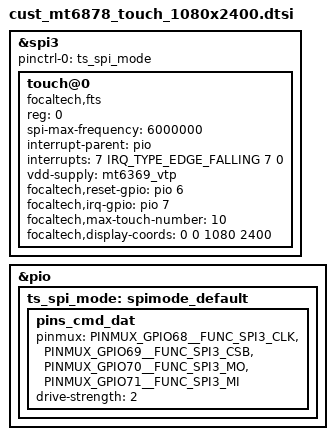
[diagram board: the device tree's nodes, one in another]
// SPDX-License-Identifier: (GPL-2.0 OR MIT)
/*
 * Copyright (C) 2020 MediaTek Inc.
 */

/* TOUCH start */

&spi3 {
	status = "okay";
	#address-cells = <1>;
	#size-cells = <0>;
	pinctrl-names = "default";
	pinctrl-0 = <&ts_spi_mode>;

	touch@0 {
		status = "okay";
		compatible = "focaltech,fts";
		reg = <0>;
		spi-max-frequency = <6000000>;
		interrupt-parent = <&pio>;
		interrupts = <7 IRQ_TYPE_EDGE_FALLING 7 0>;
		vdd-supply = <&mt6369_vtp>;
		//vcc_i2c-supply = <&mt6377_vio18>;
		focaltech,reset-gpio = <&pio 6 0x0>;
		focaltech,irq-gpio = <&pio 7 0x0>;
		focaltech,max-touch-number = <10>;
		focaltech,display-coords = <0 0 1080 2400>;
	};
};
&pio {

	ts_spi_mode: spimode_default {
		pins_cmd_dat {
			pinmux = <PINMUX_GPIO68__FUNC_SPI3_CLK>,
				<PINMUX_GPIO69__FUNC_SPI3_CSB>,
				<PINMUX_GPIO70__FUNC_SPI3_MO>,
				<PINMUX_GPIO71__FUNC_SPI3_MI>;
			drive-strength = <2>;
		};
	};
};
/* TOUCH end */
